# AC7840x register map
Vendor: AutoChips; Series: AC78; File version: 1.0
CPU: CM4 r0p1, little endian, MPU, FPU, VTOR, 4 interrupt priority bits
Registers are 32-bit, read-write, reset 0x0 unless marked. A register's access mark holds for its fields unless they carry their own. Offsets are from the block's base; [hi:lo] are bit positions; {n}, {i} and the like mark numbered series; 'fields as' and 'values as' point back to an identical list.

## MPU — Memory protection unit
Base 0x40087000
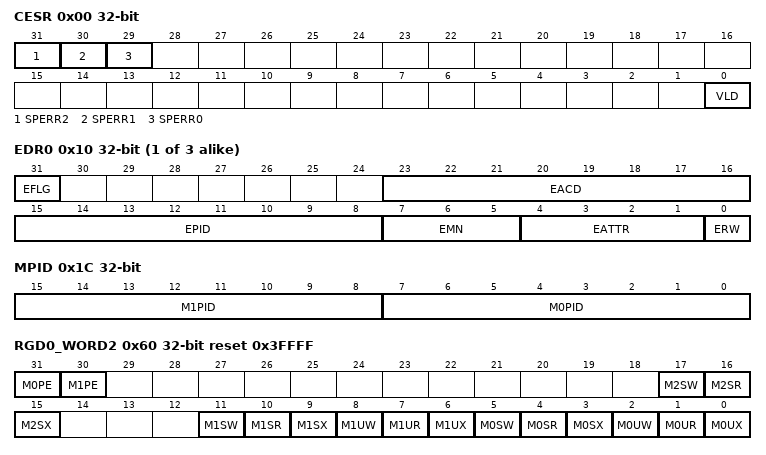
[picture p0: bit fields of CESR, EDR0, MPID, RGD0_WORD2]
0x00 CESR — Control/Error Status Register
  [31] SPERR2 — Slave Port 2 SRAM_U Error
    0=No error has occurred for Slave Port 2 SRAM_U; 1=An error has occurred for Slave Port 2 SRAM_U
  [30] SPERR1 — Slave Port 1 SRAM_L Error
    0=No error has occurred for Slave Port 1 SRAM_L; 1=An error has occurred for Slave Port 1 SRAM_L
  [29] SPERR0 — SRAM_U Slave Port 0 FLASH Error
    0=No error has occurred for Slave Port 0 FLASH; 1=An error has occurred for Slave Port 0 FLASH
  [0] VLD — Valid
    0=MPU is disabled. All accesses from all bus masters are allowed.; 1=MPU is enabled
{0x4+4i} EAR{i} ro (i=0..2) — Error Address Register, slave port {i}
  [31:0] EADDR — Error Address
{0x10+4i} EDR{i} ro (i=0..2) — Error Detail Register, slave port {i}
  [31] EFLG — Error Flag
  [23:16] EACD — Error Access Control Detail
  [15:8] EPID — Error Process Identification
  [7:5] EMN — Error Master Number
  [4:1] EATTR — Error Attributes
    1=User mode, instruction access; 2=User mode, data access; 4=Supervisor mode, instruction access; 8=Supervisor mode, data access
  [0] ERW — Error Read/Write
    0=Read; 1=Write
0x1C MPID — Master Access PID
  [15:8] M1PID — Debug Master Access PID
  [7:0] M0PID — Core Master Access PID
{0x20+4i} RGD{i}_WORD0 (i=0..7) — Region Descriptor {i}, Word 0
  [31:5] SRTADDR — Start Address
0x40 RGD0_WORD1 reset 0xFFFFFFFF — Region Descriptor 0, Word 1
  [31:5] ENDADDR — End Address
{0x40+4i} RGD{i}_WORD1 (i=1..3) — Region Descriptor {i}, Word 1
  [31:5] ENDADDR — End Address
{0x40+4i} RGD{i}_WORD1 (i=4..7) — Region Descriptor {i-1}, Word 1
  [31:5] ENDADDR — End Address
0x60 RGD0_WORD2 reset 0x3FFFF — Region Descriptor 0, Word 2
  [31] M0PE — Bus Master 0 Process Identifier enable
    0=Do not include the process identifier in the evaluation; 1=Include the process identifier and mask (RGDn.RGDAAC) in the region hit evaluation
  [30] M1PE — Bus Master 1 Process Identifier enable
    values as M0PE
  [17] M2SW — Master 2 Supervisor Mode Write(W) Access Control
    0=invalid; 1=valid
  [16] M2SR — Master 2 Supervisor Mode Read(R) Access Control
    0=invalid; 1=valid
  [15] M2SX — Master 2 Supervisor Mode Execute(X) Access Control
    0=invalid; 1=valid
  [11] M1SW — Master 1 Supervisor Mode Write(W) Access Control
    0=invalid; 1=valid
  [10] M1SR — Master 1 Supervisor Mode Read(R) Access Control
    0=invalid; 1=valid
  [9] M1SX — Master 1 Supervisor Mode Execute(X) Access Control
    0=invalid; 1=valid
  [8] M1UW — Master 1 User Mode Write(W) Access Control
    0=invalid; 1=valid
  [7] M1UR — Master 1 User Mode Read(R) Access Control
    0=invalid; 1=valid
  [6] M1UX — Master 1 User Mode Execute(X) Access Control
    0=invalid; 1=valid
  [5] M0SW — Master 0 Supervisor Mode Write(W) Access Control
    0=invalid; 1=valid
  [4] M0SR — Master 0 Supervisor Mode Read(R) Access Control
    0=invalid; 1=valid
  [3] M0SX — Master 0 Supervisor Mode Execute(X) Access Control
    0=invalid; 1=valid
  [2] M0UW — Master 0 User Mode Write(W) Access Control
    0=invalid; 1=valid
  [1] M0UR — Master 0 User Mode Read(R) Access Control
    0=invalid; 1=valid
  [0] M0UX — Master 0 User Mode Execute(X) Access Control
    0=invalid; 1=valid
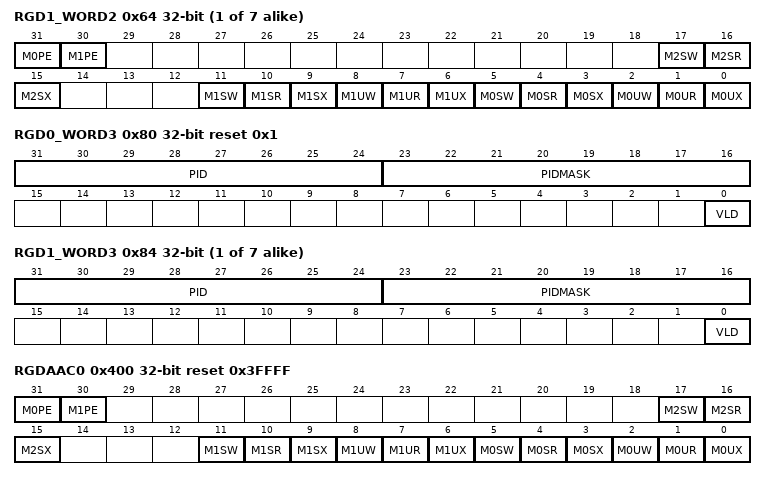
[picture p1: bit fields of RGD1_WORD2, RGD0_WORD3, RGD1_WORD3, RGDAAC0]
{0x60+4i} RGD{i}_WORD2 (i=1..7) — Region Descriptor {i}, Word 2
  fields as RGD0_WORD2
0x80 RGD0_WORD3 reset 0x1 — Region Descriptor 0, Word 3
  [31:24] PID — Process Identifier
  [23:16] PIDMASK — Process Identifier Mask
  [0] VLD — Valid
    0=Region descriptor is invalid; 1=Region descriptor is valid
{0x80+4i} RGD{i}_WORD3 (i=1..7) — Region Descriptor {i}, Word 3
  fields as RGD0_WORD3
0x400 RGDAAC0 reset 0x3FFFF — Region Descriptor Alternate Access Control 0
  fields as RGD0_WORD2
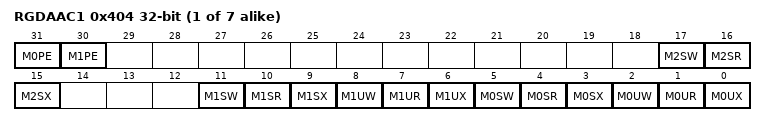
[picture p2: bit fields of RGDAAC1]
{0x400+4i} RGDAAC{i} (i=1..7) — Region Descriptor Alternate Access Control {i}
  fields as RGD0_WORD2
